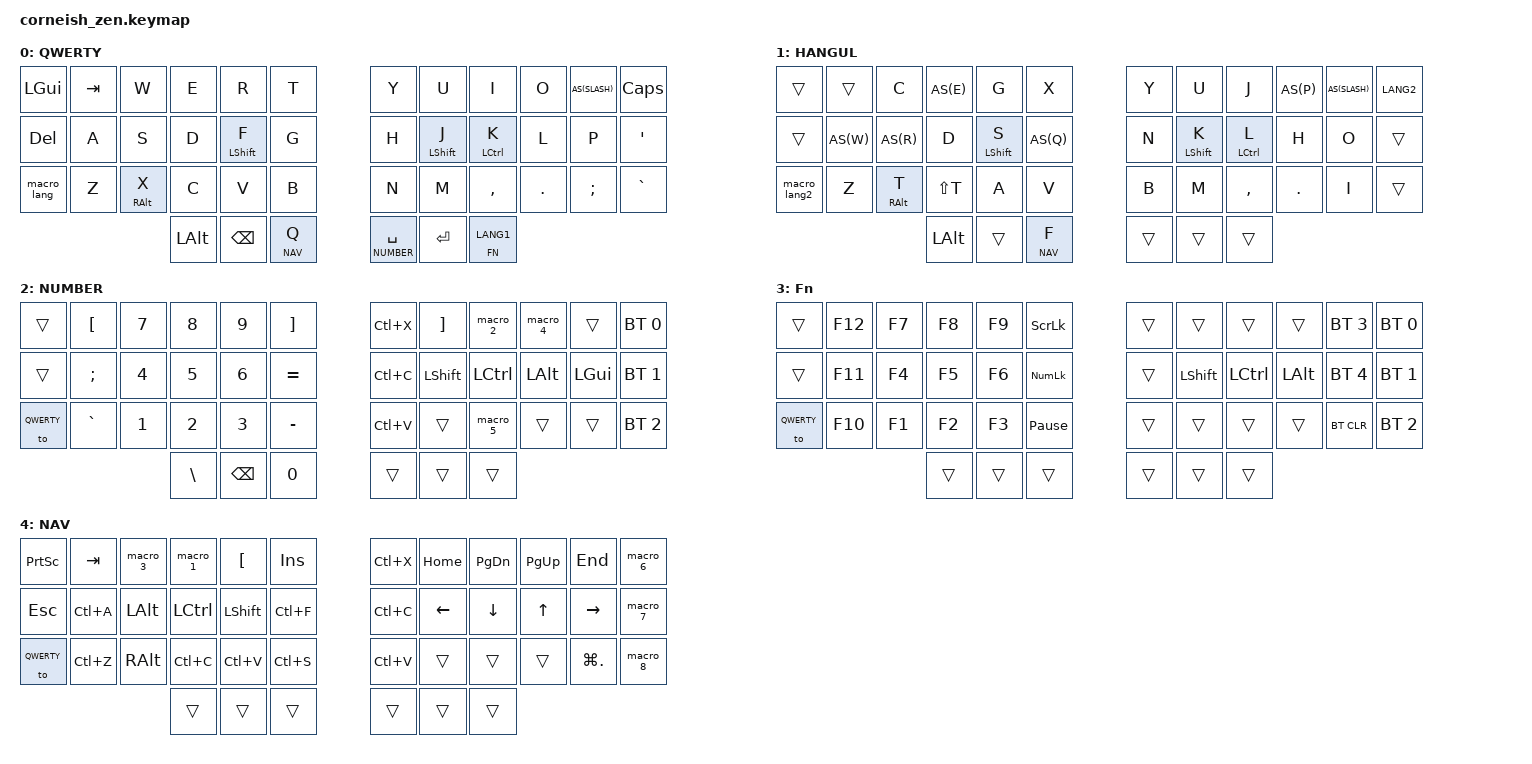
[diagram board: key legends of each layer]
#include <behaviors.dtsi>
#include <dt-bindings/zmk/keys.h>
#include <dt-bindings/zmk/bt.h>

#define QWERTY   0
#define HANGUL   1
#define NUMBER   2
#define FN       3
#define NAV      4
/ {
  chosen {
    zmk,matrix_transform = &default_transform;
    //zmk,matrix_transform = &five_column_transform;
  };
};

#define AS(keycode) &as LS(keycode) keycode

&lt { 
tapping-term-ms = <190>; 
flavor = "tap-preferred";
};

/ {
    macros {
	    macro_1: macro_1 {
			compatible = "zmk,behavior-macro";
			label = "macro_1";
			#binding-cells = <0>;
			bindings = <&kp LPAR>, <&kp LBRC>;
		};
        macro_2: macro_2 {
			compatible = "zmk,behavior-macro";
			label = "macro_2";
			#binding-cells = <0>;
			bindings = <&kp RPAR>, <&kp RBRC>;
		};
        macro_3: macro_3 {
			compatible = "zmk,behavior-macro";
			label = "macro_3";
			#binding-cells = <0>;
			bindings = <&kp LBKT>, <&kp LPAR>;
		};
        macro_4: macro_4 {
			compatible = "zmk,behavior-macro";
			label = "macro_4";
			#binding-cells = <0>;
			bindings = <&kp RBKT>, <&kp RPAR>;
		};        
        macro_5: macro_5 {
			compatible = "zmk,behavior-macro";
			label = "macro_5";
			#binding-cells = <0>;
			bindings = <&kp LBRC>, <&kp DOT>, <&kp DOT>;
		};
		        macro_6: macro_6 {
			compatible = "zmk,behavior-macro";
			label = "macro_6";
			#binding-cells = <0>;
			bindings 
			= <&macro_press &kp LCTRL>
			, <&macro_tap &kp M &kp R >
            , <&macro_release &kp LCTRL>;
		};
		        macro_7: macro_7 {
			compatible = "zmk,behavior-macro";
			label = "macro_7";
			#binding-cells = <0>;
			bindings 
			= <&macro_press &kp LCTRL>
			, <&macro_tap &kp M &kp C >
            , <&macro_release &kp LCTRL>;
		};
		        macro_8: macro_8 {
			compatible = "zmk,behavior-macro";
			label = "macro_8";
			#binding-cells = <0>;
			bindings 
			= <&macro_press &kp LCTRL>
			, <&macro_tap &kp M &kp K >
            , <&macro_release &kp LCTRL>;
		};
		macro_lang: macro_lang {
	compatible = "zmk,behavior-macro";
	label = "macro_lang";
	#binding-cells = <0>;
	bindings = <&tog HANGUL>, <&kp LANG1>;
	};
		macro_lang2: macro_lang2 {
	compatible = "zmk,behavior-macro";
	label = "macro_lang2";
	#binding-cells = <0>;
	bindings = <&to QWERTY>, <&kp LANG1>;
	};
        };
        behaviors {
            as: auto_shift {
                compatible = "zmk,behavior-hold-tap";
                label = "AUTO_SHIFT";
                #binding-cells = <2>;
                tapping_term_ms = <170>;
                quick_tap_ms = <0>;
                flavor = "tap-preferred";
                bindings = <&kp>, <&kp>;
            };
	     hm: homerow_mods {
            compatible = "zmk,behavior-hold-tap";
            label = "HOMEROW_MODS";
            #binding-cells = <2>;
            tapping-term-ms = <210>;
            quick_tap_ms = <0>;
            flavor = "tap-preferred";
            bindings = <&kp>, <&kp>;
        };
	};

        keymap {
                compatible = "zmk,keymap";

                QWERTY_layer {
                        label = "QWERTY";
// -----------------------------------------------------------------------------------------
// |  WIN | TAB |  W  |  E  |  R  |  T  |   |   Y   |  U   |  I  |  O  |  /  | caps |
// |  DEL |  A  |  S  |  D  | S(F)|  G  |   |   H   |  J   |  K  |  L  |  P  |  '   |
// | hanen|  Z  | A(X)|  C  |  V  |  B  |   |   N   |  M   |  ,  |  .  |  ;  |  `~  |
//                    |mouse| BKSP|Q/nav|   |SPC/NUM|ENT/SY| Fn |
                        bindings = <
   &kp LGUI    &kp TAB &kp W      &kp E &kp R        &kp T           &kp Y      &kp U         &kp I         &kp O   AS(SLASH)    &kp CAPSLOCK
   &kp DEL     &kp A   &kp S      &kp D &hm LSHIFT F &kp G           &kp H      &hm LSHIFT J  &hm LCTRL K   &kp L   &kp P        &kp SQT
   &macro_lang &kp Z   &hm RALT X &kp C &kp V        &kp B           &kp N      &kp M         &kp COMMA     &kp DOT &kp SEMI     &kp GRAVE
                  &kp LALT  &kp BSPC &lt NAV Q                    &lt NUMBER SPACE &kp ENTER &lt FN LANG1
                        >;
                };
                HANGUL_layer {
                        label = "HANGUL";
// -----------------------------------------------------------------------------------------
// |  win | tap |  c  |  e  |  g  |  x  |   |  y    |  u   |  j  |  p  |  /  | hanja |
// |  del |  w  |  r  |  d  | Ss  |  q  |   |  n    |  k   |  l  |  h  |  o  |   '   |
// | hanen|  z  | At  |  T  |  a  |  v  |   |  b    |  m   |  ,  |  .  |  i  |   `~  |
//                    | mou |bksp |Q/nav|   |SPC/NUM|ent/sy| fn |
                        bindings = <
   &trans  &trans  &kp C       AS(E)     &kp G        &kp X               &kp Y    &kp U         &kp J        AS(P)   AS(SLASH) &kp LANG2
   &trans  AS(W)   AS(R)       &kp D     &hm LSHIFT S AS(Q)               &kp N    &hm LSHIFT K  &hm LCTRL L        &kp H   &kp O     &trans
   &macro_lang2  &kp Z   &hm RALT T  &kp LS(T) &kp A        &kp V               &kp B    &kp M         &kp COMMA    &kp DOT &kp I     &trans
                          	       &kp LALT   &trans &lt NAV F          &trans   &trans   &trans
                        >;
                };
				               number_layer {
                        label = "NUMBER";
// -----------------------------------------------------------------------------------------
// |  win |  [  |  7  |  8  |  9  |  ]  |   | CUT  |  ]  |  ”  |  ’  |  0    | BT0  |
// |  del |  ;  |  4  |  5  |  6  |  =+ |   | COPY |LSHFT|LCTRL| LALT| LGUI  | BT1  |
// | hanen|  `  |  2  |  2  |  3  |  -  |   |PASTE |     |  …  |     |       | BT2  |
//                    |  \| |     |  0  |   |      |     |     |
                        bindings = <
  &trans  &kp LBKT  &kp N7 &kp N8 &kp N9   &kp RBKT          &kp LC(X)  &kp RBKT   &macro_2     &macro_4     &trans   &bt BT_SEL 0
  &trans  &kp SEMI  &kp N4 &kp N5 &kp N6   &kp EQUAL         &kp LC(C)  &kp LSHFT  &kp LCTRL    &kp LALT     &kp LGUI &bt BT_SEL 1
  &to QWERTY  &kp GRAVE &kp N1 &kp N2 &kp N3   &kp MINUS         &kp LC(V)  &trans     &macro_5     &trans       &trans   &bt BT_SEL 2
                        &kp BSLH &kp BSPC  &kp N0     &trans   &trans   &trans
                        >;
                };
				               fn_layer {
                        label = "Fn";
// -----------------------------------------------------------------------------------------
// |     |  1  |  2  |  3  |  4  |  5  |   |  6  |  7  |  8  |  9  |  0  | BKSP |
// |     | BT1 | BT2 | BT3 | BT4 | BT5 |   | LFT | DWN |  UP | RGT |     |      |
// |     |     |     |     |     |     |   |     |     |     |     |     |      |
//                    | GUI |     | SPC |   | ENT |     | ALT |
                        bindings = <
	&trans  &kp F12 &kp F7 &kp F8 &kp F9   &kp SCROLLLOCK            &trans  &trans     &trans    &trans    &bt BT_SEL 3   &bt BT_SEL 0
	&trans  &kp F11 &kp F4 &kp F5 &kp F6   &kp KP_NUM                &trans  &kp LSHFT  &kp LCTRL &kp LALT  &bt BT_SEL 4 &bt BT_SEL 1
 	&to QWERTY &kp F10 &kp F1 &kp F2 &kp F3   &kp PAUSE_BREAK        &trans  &trans     &trans    &trans    &bt BT_CLR   &bt BT_SEL 2
                    &trans        &trans   &trans                    &trans  &trans     &trans 
                        >;
                };
				               nav_layer {
                        label = "NAV";
// -----------------------------------------------------------------------------------------
// |  PACR  |  1  |  ‘  |  “  |  [  |insert|   |     |HOME |PGDN | PGUP|  END |H RED|
// |  ESC   | CA  | LALT|LCTRL|LSHFT|  CF  |   |     | LFT | DWN |  UP | RGT  |H BG |
// |        | CZ  | RALT| CC  |  CV |  CS  |   |     |     |     |     | EMOJI|H BK |
//                |     |     |     |      |   |     |     |
                        bindings = <
 	&kp PSCRN     &kp TAB   &macro_3    &macro_1     &kp LBKT  &kp INS                                 &kp LC(X) &kp HOME &kp PG_DN &kp PG_UP &kp END   &macro_6
	&kp ESC       &kp LC(A) &kp LALT    &kp LCTRL    &kp LSHFT &kp LC(F)                               &kp LC(C) &kp LEFT &kp DOWN  &kp UP    &kp RIGHT &macro_7
    &to QWERTY &kp LC(Z) &kp RALT    &kp LC(C)    &kp LC(V) &kp LC(S)                               &kp LC(V) &trans   &trans    &trans    &kp LG(DOT)  &macro_8
                          	        &trans       &trans    &trans      &trans  &trans         &trans 
                        >;
                };

        };
};
